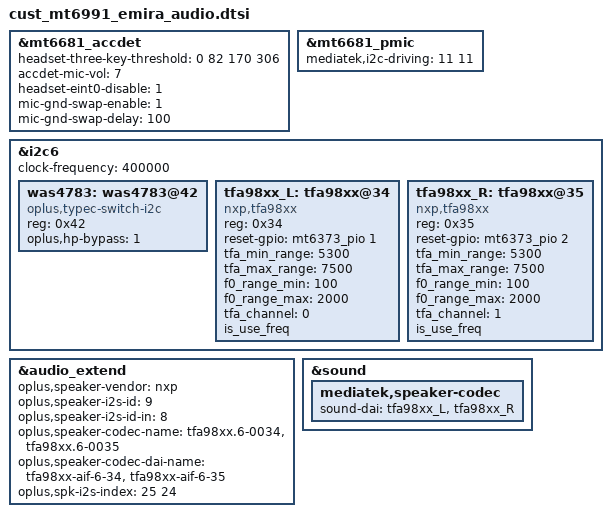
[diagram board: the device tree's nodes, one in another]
// SPDX-License-Identifier: GPL-2.0
/* Copyright (c) 2020 MediaTek Inc. */
#include <dt-bindings/pinctrl/mt6373-pinfunc.h>

&mt6681_accdet {
	headset-three-key-threshold = <0 82 170 306>;
	accdet-mic-vol = <7>;
	// add for supporting type-c headphone detect bypass
	headset-eint0-disable = <1>;
	mic-gnd-swap-enable = <1>;
	mic-gnd-swap-delay = <100>;
};

&mt6681_pmic {
	mediatek,i2c-driving = <11 11>;
};

&i2c6 {
	clock-frequency = <400000>;

	was4783: was4783@42 {
		compatible = "oplus,typec-switch-i2c";
		reg = <0x42>;
		// add for supporting type-c headphone detect bypass
		oplus,hp-bypass = <1>;
		status = "okay";
	};

	tfa98xx_L: tfa98xx@34{
		compatible = "nxp,tfa98xx";
		reg = <0x34>;
		reset-gpio = <&mt6373_pio 1 0>;
		tfa_min_range = <5300>;
		tfa_max_range = <7500>;
		f0_range_min = <100>;
		f0_range_max = <2000>;
		tfa_channel = <0>;
		is_use_freq;
		status = "okay";
	};

	tfa98xx_R: tfa98xx@35{
		compatible = "nxp,tfa98xx";
		reg = <0x35>;
		reset-gpio = <&mt6373_pio 2 0>;
		tfa_min_range = <5300>;
		tfa_max_range = <7500>;
		f0_range_min = <100>;
		f0_range_max = <2000>;
		tfa_channel = <1>;
		is_use_freq;
		status = "okay";
	};

};

&audio_extend {
 	//for nxp speaker
 	oplus,speaker-vendor = "nxp";
 	oplus,speaker-i2s-id = <9>;
 	oplus,speaker-i2s-id-in = <8>;
	oplus,speaker-codec-name = "tfa98xx.6-0034","tfa98xx.6-0035";
	oplus,speaker-codec-dai-name = "tfa98xx-aif-6-34","tfa98xx-aif-6-35";
	oplus,spk-i2s-index = <25 24>;
};

&sound {
//	mtk_spk_i2s_out = <3>;
//	mtk_spk_i2s_in = <9>;
	mediatek,speaker-codec {
		sound-dai = <&tfa98xx_L>, <&tfa98xx_R>;
	};

};
